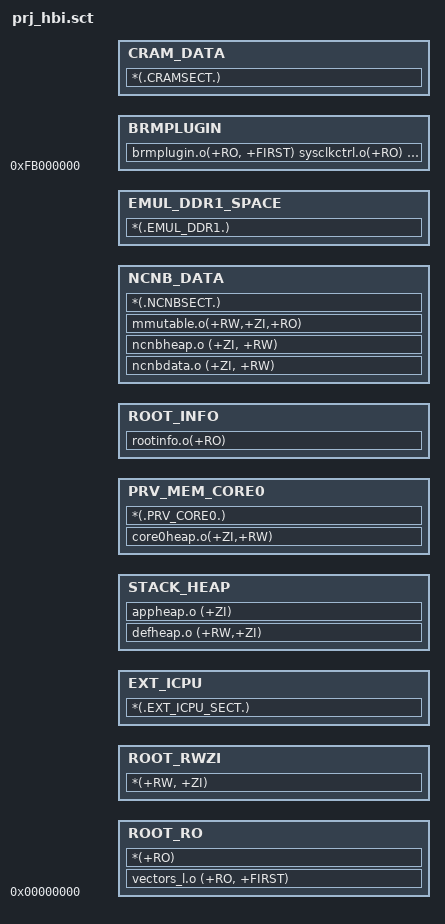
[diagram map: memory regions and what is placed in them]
#! armcc -E

#define LARM_IMAGE_BASE 0x000000
#include "../SYSCORE/SERVICES/memcfg.h"

ROOT LARM_IMAGE_BASE
{
    ROOT_RO LARM_IMAGE_BASE 
    {
        vectors_l.o (+RO, +FIRST)
        *(+RO)
    }

    ROOT_RWZI (LARM_IMAGE_BASE+ROOT_RO_SIZE)
    {
        *(+RW, +ZI)
    }
    EXT_ICPU (LARM_IMAGE_BASE+ROOT_RO_SIZE+ROOT_RW_SIZE)
    {
        *(.EXT_ICPU_SECT.)
    }

    STACK_HEAP (LARM_IMAGE_BASE+ROOT_RO_SIZE+ROOT_RW_SIZE+ROOT_ICPUV2_SIZE)
    {
        defheap.o (+RW,+ZI)
        appheap.o (+ZI)
    }
}

PRV_MEM_CORE0 (LARM_IMAGE_BASE+ROOT_RO_SIZE+ROOT_RW_SIZE+ROOT_ICPUV2_SIZE+ROOT_HEAP_SIZE) ROOT_PRV_CORE0_MEM_SIZE
{
    PRV_MEM_CORE0 (LARM_IMAGE_BASE+ROOT_RO_SIZE+ROOT_RW_SIZE+ROOT_ICPUV2_SIZE+ROOT_HEAP_SIZE)
    {
        core0heap.o(+ZI,+RW)
        *(.PRV_CORE0.)
    }
}

ROOT_INFO (LARM_IMAGE_BASE+ROOT_RO_SIZE+ROOT_RW_SIZE+ROOT_ICPUV2_SIZE+ROOT_HEAP_SIZE+ROOT_PRV_CORE0_MEM_SIZE) ROOT_INFO_SIZE
{
    ROOT_INFO (LARM_IMAGE_BASE+ROOT_RO_SIZE+ROOT_RW_SIZE+ROOT_ICPUV2_SIZE+ROOT_HEAP_SIZE+ROOT_PRV_CORE0_MEM_SIZE) ROOT_INFO_SIZE
    {
        rootinfo.o(+RO)
    }
}

NCNB_DATA (LARM_IMAGE_BASE+ROOT_RO_SIZE+ROOT_RW_SIZE+ROOT_ICPUV2_SIZE+ROOT_HEAP_SIZE+ROOT_PRV_CORE0_MEM_SIZE+ROOT_INFO_SIZE) 
{
    NCNB_DATA (LARM_IMAGE_BASE+ROOT_RO_SIZE+ROOT_RW_SIZE+ROOT_ICPUV2_SIZE+ROOT_HEAP_SIZE+ROOT_PRV_CORE0_MEM_SIZE+ROOT_INFO_SIZE)
    {
        ncnbdata.o (+ZI, +RW)
        ncnbheap.o (+ZI, +RW)
        mmutable.o(+RW,+ZI,+RO)
        *(.NCNBSECT.)
    }

    EMUL_DDR1_SPACE (LARM_IMAGE_BASE+ROOT_RO_SIZE+ROOT_RW_SIZE+ROOT_ICPUV2_SIZE+ROOT_HEAP_SIZE+ROOT_PRV_CORE0_MEM_SIZE+ROOT_INFO_SIZE+ROOT_NCNB_SIZE)
    {
       *(.EMUL_DDR1.)
    }
}

BRMPLUGIN 0xFB000000 0x20000
{
    BRMPLUGIN 0xFB000000
    {
        brmplugin.o(+RO, +FIRST) sysclkctrl.o(+RO) sysddrctrl.o(+RO)
    }
}

CRAM_DATA CRAM_VAR_BASE CRAM_VAR_SIZE
{
    CRAM_DATA CRAM_VAR_BASE CRAM_VAR_SIZE
    {
        *(.CRAMSECT.)
    }
}
